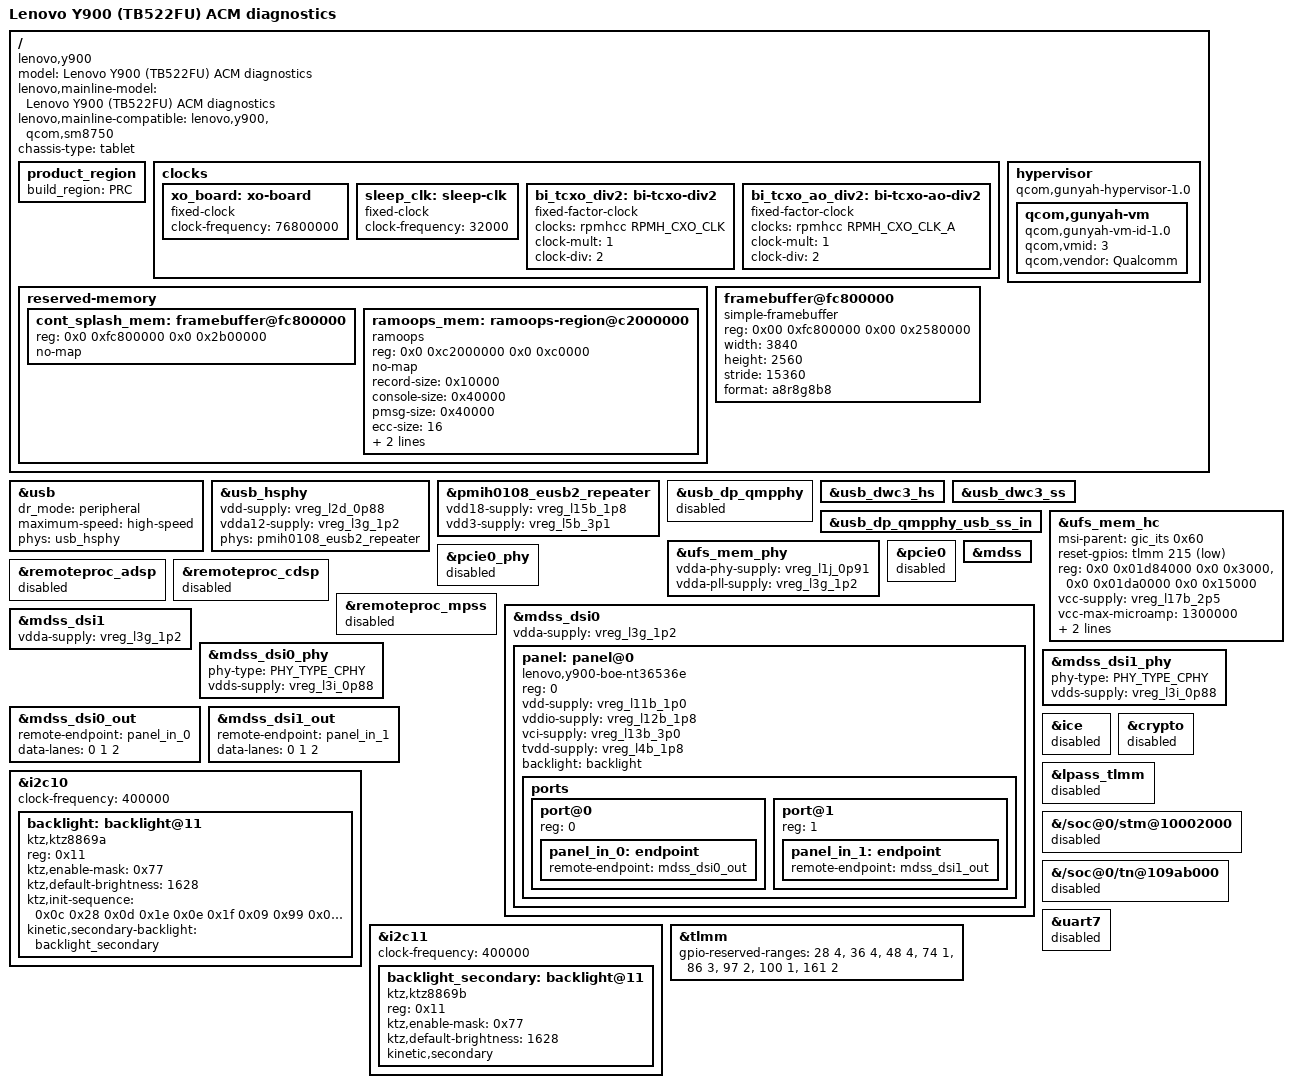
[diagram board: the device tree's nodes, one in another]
// SPDX-License-Identifier: BSD-3-Clause
// Lenovo Y900 (TB522FU) ACM diagnostic board.
/dts-v1/;
#include <dt-bindings/gpio/gpio.h>
#include <dt-bindings/phy/phy.h>
#include <dt-bindings/regulator/qcom,rpmh-regulator.h>
#include "sm8750.dtsi"
#include "pm8550.dtsi"
#include "pmih0108.dtsi"
#include "pmk8550.dtsi"
#include "sm8750-pmics.dtsi"
#include "sm8750-lenovo-y900-regulators.dtsi"

/ {
	model = "Lenovo Y900 (TB522FU) ACM diagnostics";
	compatible = "lenovo,y900", "qcom,sm8750";
	lenovo,mainline-model = "Lenovo Y900 (TB522FU) ACM diagnostics";
	lenovo,mainline-compatible = "lenovo,y900", "qcom,sm8750";
	chassis-type = "tablet";
	product_region { build_region = "PRC"; };

	clocks {
		xo_board: xo-board {
			compatible = "fixed-clock";
			clock-frequency = <76800000>;
			#clock-cells = <0>;
		};

		sleep_clk: sleep-clk {
			compatible = "fixed-clock";
			clock-frequency = <32000>;
			#clock-cells = <0>;
		};

		bi_tcxo_div2: bi-tcxo-div2 {
			compatible = "fixed-factor-clock";
			#clock-cells = <0>;
			clocks = <&rpmhcc RPMH_CXO_CLK>;
			clock-mult = <1>;
			clock-div = <2>;
		};

		bi_tcxo_ao_div2: bi-tcxo-ao-div2 {
			compatible = "fixed-factor-clock";
			#clock-cells = <0>;
			clocks = <&rpmhcc RPMH_CXO_CLK_A>;
			clock-mult = <1>;
			clock-div = <2>;
		};
	};

	hypervisor {
		compatible = "qcom,gunyah-hypervisor-1.0", "qcom,gunyah-hypervisor", "simple-bus";
		#address-cells = <2>;
		#size-cells = <0>;

		qcom,gunyah-vm {
			compatible = "qcom,gunyah-vm-id-1.0", "qcom,gunyah-vm-id";
			qcom,vmid = <3>;
			qcom,vendor = "Qualcomm";
		};
	};
};

&usb {
	status = "okay";
	dr_mode = "peripheral";
	maximum-speed = "high-speed";
	phys = <&usb_hsphy>;
	phy-names = "usb2-phy";
	/delete-property/ usb-role-switch;
};

&usb_hsphy {
	vdd-supply = <&vreg_l2d_0p88>;
	vdda12-supply = <&vreg_l3g_1p2>;
	phys = <&pmih0108_eusb2_repeater>;
	status = "okay";
};

&pmih0108_eusb2_repeater {
	vdd18-supply = <&vreg_l15b_1p8>;
	vdd3-supply = <&vreg_l5b_3p1>;
	status = "okay";
};

&usb_dp_qmpphy { status = "disabled"; };
&usb_dwc3_hs { /delete-property/ remote-endpoint; };
&usb_dwc3_ss { /delete-property/ remote-endpoint; };
&usb_dp_qmpphy_usb_ss_in { /delete-property/ remote-endpoint; };

&ufs_mem_hc {
	status = "okay";
	msi-parent = <&gic_its 0x60>;
	reset-gpios = <&tlmm 215 GPIO_ACTIVE_LOW>;
	reg = <0x0 0x01d84000 0x0 0x3000>, <0x0 0x01da0000 0x0 0x15000>;
	reg-names = "std", "mcq";
	vcc-supply = <&vreg_l17b_2p5>;
	vcc-max-microamp = <1300000>;
	vccq-supply = <&vreg_l1d_1p2>;
	vccq-max-microamp = <1200000>;
};

&ufs_mem_phy {
	status = "okay";
	vdda-phy-supply = <&vreg_l1j_0p91>;
	vdda-pll-supply = <&vreg_l3g_1p2>;
};

&pcie0 { status = "disabled"; };
&pcie0_phy { status = "disabled"; };
&remoteproc_adsp { status = "disabled"; };
&remoteproc_cdsp { status = "disabled"; };
&remoteproc_mpss { status = "disabled"; };

&mdss {
	status = "okay";
};

&mdss_dsi0 {
	vdda-supply = <&vreg_l3g_1p2>;
	status = "okay";

	panel: panel@0 {
		compatible = "lenovo,y900-boe-nt36536e";
		reg = <0>;

		vdd-supply = <&vreg_l11b_1p0>;
		vddio-supply = <&vreg_l12b_1p8>;
		vci-supply = <&vreg_l13b_3p0>;
		tvdd-supply = <&vreg_l4b_1p8>;
		backlight = <&backlight>;

		/*
		 * GPIO 98 (reset) and GPIO 86 (TE) are TUIC-secure pages in
		 * this Gunyah VM.  Do not request them from Linux; ABL has
		 * already released the panel reset.  The DSI video path does
		 * not require TE.
		 */

		ports {
			#address-cells = <1>;
			#size-cells = <0>;

			port@0 {
				reg = <0>;

				panel_in_0: endpoint {
					remote-endpoint = <&mdss_dsi0_out>;
				};
			};

			port@1 {
				reg = <1>;

				panel_in_1: endpoint {
					remote-endpoint = <&mdss_dsi1_out>;
				};
			};
		};
	};
};

&mdss_dsi1 {
	vdda-supply = <&vreg_l3g_1p2>;
	status = "okay";
};

&mdss_dsi0_phy {
	phy-type = <PHY_TYPE_CPHY>;
	vdds-supply = <&vreg_l3i_0p88>;
	status = "okay";
};

&mdss_dsi1_phy {
	phy-type = <PHY_TYPE_CPHY>;
	vdds-supply = <&vreg_l3i_0p88>;
	status = "okay";
};

&mdss_dsi0_out {
	remote-endpoint = <&panel_in_0>;
	data-lanes = <0 1 2>;
};

&mdss_dsi1_out {
	remote-endpoint = <&panel_in_1>;
	data-lanes = <0 1 2>;
};

&i2c10 {
	status = "okay";
	clock-frequency = <400000>;

	backlight: backlight@11 {
		compatible = "ktz,ktz8869a";
		reg = <0x11>;
		ktz,enable-mask = <0x77>;
		ktz,default-brightness = <1628>;
		ktz,init-sequence = /bits/ 8 <
			0x0c 0x28 0x0d 0x1e 0x0e 0x1f 0x09 0x99
			0x02 0xd2 0x15 0xf5 0x03 0xed 0x14 0xaa
			0x11 0x77 0x08 0x77 0x04 0x0c 0x05 0x65
			0x01 0x01
		>;
		kinetic,secondary-backlight = <&backlight_secondary>;
	};
};

&i2c11 {
	status = "okay";
	clock-frequency = <400000>;

	backlight_secondary: backlight@11 {
		compatible = "ktz,ktz8869b";
		reg = <0x11>;
		ktz,enable-mask = <0x77>;
		ktz,default-brightness = <1628>;
		kinetic,secondary;
	};
};

&ice { status = "disabled"; };
&crypto { status = "disabled"; };
&lpass_tlmm { status = "disabled"; };
&{/soc@0/stm@10002000} { status = "disabled"; };
&{/soc@0/tn@109ab000} { status = "disabled"; };
&{/reserved-memory} { /delete-node/ demura_region_0; /delete-node/ demura_region_1; };

&tlmm {
	gpio-reserved-ranges = <28 4>, <36 4>, <48 4>, <74 1>, <86 3>, <97 2>, <100 1>, <161 2>;
};

/ {
	reserved-memory {
		cont_splash_mem: framebuffer@fc800000 {
			reg = <0x0 0xfc800000 0x0 0x2b00000>;
			no-map;
		};

		ramoops_mem: ramoops-region@c2000000 {
			reg = <0x0 0xc2000000 0x0 0xc0000>;
			no-map;
		};
	};
};

&ramoops_mem {
	compatible = "ramoops";
	record-size = <0x10000>;
	console-size = <0x40000>;
	pmsg-size = <0x40000>;
	ecc-size = <16>;
	mem-type = <2>;
	max-reason = <4>;
};

&uart7 { status = "disabled"; };

/ {
	framebuffer@fc800000 {
		compatible = "simple-framebuffer";
		reg = <0x00 0xfc800000 0x00 0x2580000>;
		width = <3840>;
		height = <2560>;
		stride = <15360>;
		format = "a8r8g8b8";
		status = "okay";
	};
};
